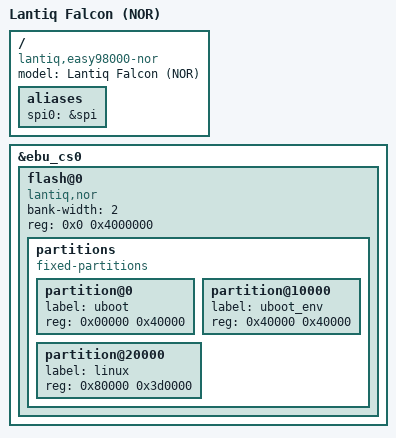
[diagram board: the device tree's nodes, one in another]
/dts-v1/;

#include "falcon_lantiq_easy98000.dtsi"

/ {
	model = "Lantiq Falcon (NOR)";
	compatible = "lantiq,easy98000-nor", "lantiq,easy98000", "lantiq,falcon";

	aliases {
		spi0 = &spi;
	};
};

&ebu_cs0 {
	flash@0 {
		compatible = "lantiq,nor";
		bank-width = <2>;
		reg = <0x0 0x4000000>;

		partitions {
			compatible = "fixed-partitions";
			#address-cells = <1>;
			#size-cells = <1>;

			partition@0 {
				label = "uboot";
				reg = <0x00000 0x40000>;
			};

			partition@10000 {
				label = "uboot_env";
				reg = <0x40000 0x40000>;
			};

			partition@20000 {
				label = "linux";
				reg = <0x80000 0x3d0000>;
			};
		};
	};
};
